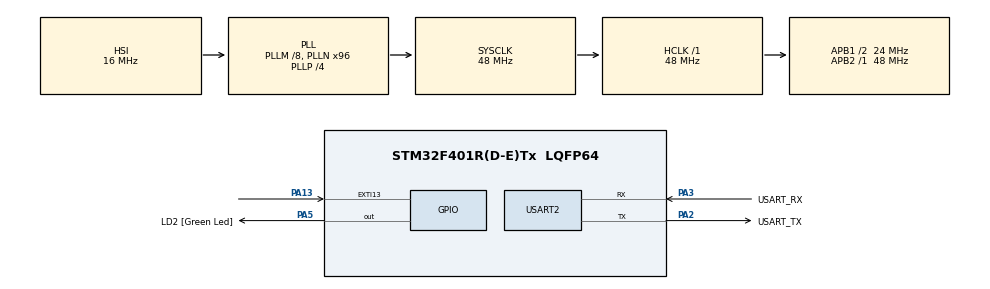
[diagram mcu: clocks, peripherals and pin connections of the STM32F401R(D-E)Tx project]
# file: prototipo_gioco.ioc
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Mcu.Family=STM32F4
Mcu.Name=STM32F401R(D-E)Tx
Mcu.Package=LQFP64
NVIC.EXTI15_10_IRQn=true\:0\:0\:false\:false\:true\:true\:true\:true
NVIC.PriorityGroup=NVIC_PRIORITYGROUP_4
NVIC.TIM2_IRQn=true\:0\:0\:false\:false\:true\:true\:true\:true
PA13.GPIO_ModeDefaultEXTI=GPIO_MODE_IT_FALLING
PA13.Signal=GPXTI13
PA14.GPIO_Label=TCK
PA14.Signal=SYS_JTCK-SWCLK
PA2.GPIO_Label=USART_TX
PA2.GPIO_Mode=GPIO_MODE_AF_PP
PA2.GPIO_PuPd=GPIO_NOPULL
PA2.GPIO_Speed=GPIO_SPEED_FREQ_LOW
PA2.Mode=Asynchronous
PA2.Signal=USART2_TX
PA3.GPIO_Label=USART_RX
PA3.GPIO_Mode=GPIO_MODE_AF_PP
PA3.GPIO_PuPd=GPIO_NOPULL
PA3.GPIO_Speed=GPIO_SPEED_FREQ_LOW
PA3.Mode=Asynchronous
PA3.Signal=USART2_RX
PA5.GPIO_Label=LD2 [Green Led]
PA5.GPIO_Mode=GPIO_MODE_OUTPUT_PP
PA5.GPIO_PuPd=GPIO_NOPULL
PA5.GPIO_Speed=GPIO_SPEED_FREQ_LOW
PA5.Signal=GPIO_Output
PB3.GPIO_Label=SWO
PB3.Signal=SYS_JTDO-SWO
PC14-OSC32_IN.Mode=LSE-External-Oscillator
PC14-OSC32_IN.Signal=RCC_OSC32_IN
PC15-OSC32_OUT.Mode=LSE-External-Oscillator
PC15-OSC32_OUT.Signal=RCC_OSC32_OUT
PH0\ -\ OSC_IN.Mode=HSE-External-Clock-Source
PH0\ -\ OSC_IN.Signal=RCC_OSC_IN
PH1\ -\ OSC_OUT.Mode=HSE-External-Clock-Source
PH1\ -\ OSC_OUT.Signal=RCC_OSC_OUT
ProjectManager.HeapSize=0x200
ProjectManager.StackSize=0x400
ProjectManager.TargetToolchain=STM32CubeIDE
RCC.48MHZClocksFreq_Value=27428571.42857143
RCC.AHBFreq_Value=48000000
RCC.APB1CLKDivider=RCC_HCLK_DIV2
RCC.APB1Freq_Value=24000000
RCC.APB1TimFreq_Value=48000000
RCC.APB2Freq_Value=48000000
RCC.APB2TimFreq_Value=48000000
RCC.CortexFreq_Value=48000000
RCC.HCLKFreq_Value=48000000
RCC.HSE_VALUE=8000000
RCC.HSI_VALUE=16000000
RCC.PLLM=8
RCC.PLLN=96
RCC.PLLP=RCC_PLLP_DIV4
RCC.PLLQ=7
RCC.SYSCLKFreq_VALUE=48000000
RCC.SYSCLKSource=RCC_SYSCLKSOURCE_PLLCLK
RCC.VCOOutputFreq_Value=192000000
TIM2.AutoReloadPreload=TIM_AUTORELOAD_PRELOAD_ENABLE
TIM2.Period=999
TIM2.Prescaler=47999
USART2.VirtualMode=VM_ASYNC
VP_TIM2_VS_ClockSourceINT.Mode=Internal
board=NUCLEO-F401RE

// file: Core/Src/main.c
/* USER CODE BEGIN Header */
/**
  ******************************************************************************
  * @file           : main.c
  * @brief          : Main program body
  ******************************************************************************
  */
/* USER CODE END Header */
#include "main.h"
#include "constants.h"
#include "game.h"
#include <stdio.h>   // Per printf
#include <stdlib.h>  // Per rand()

TIM_HandleTypeDef htim2;
UART_HandleTypeDef huart2;

/* USER CODE BEGIN PV */
volatile uint8_t buttonPressed = 0; // 0 se non premuto, 1 se premuto
volatile uint8_t start = 0;

int timer_value = 0; // valuta tempo di risposta

/* USER CODE END PV */

void SystemClock_Config(void);
static void MX_GPIO_Init(void);
static void MX_TIM2_Init(void);
static void MX_USART2_UART_Init(void);

/* USER CODE BEGIN PFP */
#ifdef __GNUC__
  #define PUTCHAR_PROTOTYPE int __io_putchar(int ch)
#else
  #define PUTCHAR_PROTOTYPE int fputc(int ch, FILE *f)
#endif

PUTCHAR_PROTOTYPE
{
  HAL_UART_Transmit(&huart2, (uint8_t *)&ch, 1, 0xFFFF);
  return ch;
}
/* USER CODE END PFP */

int main(void)
{
  /* Reset of all peripherals, Initializes the Flash interface and the Systick. */
  HAL_Init();

  /* Configure the system clock */
  SystemClock_Config();

  /* Initialize all configured peripherals */
  MX_GPIO_Init();
  MX_TIM2_Init();
  MX_USART2_UART_Init();

  /* USER CODE BEGIN 2 */
  // Leggiamo un valore a caso dalla memoria per inizializzare il random

  printf("\r\n=== RHYTHM GAME PROTOTYPE ===\r\n");
  //createDummySong();
  /* USER CODE END 2 */

  /* Infinite loop */
  /* USER CODE BEGIN WHILE */
  while (1)
  {
	  printf("press the button to start \n");
	  buttonPressed = 0; //to clear from older clicks
	  start = 1; // evaluate the button press

	  while (buttonPressed == 0){
		  //waiting for game to start
	  }
	  start = 0; //start phase finished
	  buttonPressed=0; //reset button to restart game
	  printf("\r\n game start! \r\n");
      printf("\r\nWAIT FOR THE LED TO TURN ON\r\n");

      // Aspetta un tempo casuale tra 2 e 5 secondi
      for(int i = 0; i < SONGLENGHT; i++){
      HAL_Delay(rand() % SECONDS + SECONDS_OFFSET);

      buttonPressed = 0;
      HAL_GPIO_WritePin(GPIOA, GPIO_PIN_5, GPIO_PIN_SET); // Accendi LD2
      printf("PRESS THE BUTTON!\r\n");

      // Azzera e fai partire il timer da 1 secondo
      __HAL_TIM_SET_COUNTER(&htim2, 0);
      HAL_TIM_Base_Start_IT(&htim2);

      // Aspetta che finisca il round (diamogli 2 secondi di pausa) prima di ripartire
      HAL_Delay(SPACE_BETWEEN_NOTES);

      // Assicuriamoci che il LED sia spento per il prossimo round
      HAL_GPIO_WritePin(GPIOA, GPIO_PIN_5, GPIO_PIN_RESET);
      }
	  finalScore(); //evaluates results
    printf("\r\n------GAME OVER, THANKS FOR PLAYING!------\r\n");
    /* USER CODE END WHILE */

  }
}

/* Callback del Pulsante (EXTI) */
/* USER CODE BEGIN 4 */
void HAL_GPIO_EXTI_Callback(uint16_t GPIO_Pin) {
    // PC13 è il Pin 13
    if (GPIO_Pin == GPIO_PIN_13 && buttonPressed == 0) {
        // Se il timer sta ancora girando (non ha fatto stop)
    	if (start == 1){
    		buttonPressed = 1;
    	}
    	else if (__HAL_TIM_GET_COUNTER(&htim2) > 0) {
            HAL_TIM_Base_Stop_IT(&htim2); // Ferma il timer! Hai vinto!
            timer_value = __HAL_TIM_GET_COUNTER(&htim2); //prendo valore timer
            buttonPressed = 1;
            HAL_GPIO_WritePin(GPIOA, GPIO_PIN_5, GPIO_PIN_RESET); // Spegni LED
            scoreEvaluate(timer_value);
        }
    }
}

/* Callback del Timer (Fine del tempo) */
void HAL_TIM_PeriodElapsedCallback(TIM_HandleTypeDef *htim) {
    if (htim->Instance == TIM2) {
        HAL_TIM_Base_Stop_IT(&htim2); // Ferma il timer per sicurezza

        if (buttonPressed == 0) { // Se non hai premuto in tempo
            HAL_GPIO_WritePin(GPIOA, GPIO_PIN_5, GPIO_PIN_RESET); // Spegni LED
            scoreEvaluate(MISSVALUE);
        }
    }
}
/* USER CODE END 4 */

void SystemClock_Config(void)
{
  RCC_OscInitTypeDef RCC_OscInitStruct = {0};
  RCC_ClkInitTypeDef RCC_ClkInitStruct = {0};

  __HAL_RCC_PWR_CLK_ENABLE();
  __HAL_PWR_VOLTAGESCALING_CONFIG(PWR_REGULATOR_VOLTAGE_SCALE2);

  RCC_OscInitStruct.OscillatorType = RCC_OSCILLATORTYPE_HSI;
  RCC_OscInitStruct.HSIState = RCC_HSI_ON;
  RCC_OscInitStruct.HSICalibrationValue = RCC_HSICALIBRATION_DEFAULT;
  RCC_OscInitStruct.PLL.PLLState = RCC_PLL_ON;
  RCC_OscInitStruct.PLL.PLLSource = RCC_PLLSOURCE_HSI;
  RCC_OscInitStruct.PLL.PLLM = 8;
  RCC_OscInitStruct.PLL.PLLN = 96;
  RCC_OscInitStruct.PLL.PLLP = RCC_PLLP_DIV4;
  RCC_OscInitStruct.PLL.PLLQ = 7;
  if (HAL_RCC_OscConfig(&RCC_OscInitStruct) != HAL_OK)
  {
    Error_Handler();
  }

  RCC_ClkInitStruct.ClockType = RCC_CLOCKTYPE_HCLK|RCC_CLOCKTYPE_SYSCLK
                              |RCC_CLOCKTYPE_PCLK1|RCC_CLOCKTYPE_PCLK2;
  RCC_ClkInitStruct.SYSCLKSource = RCC_SYSCLKSOURCE_PLLCLK;
  RCC_ClkInitStruct.AHBCLKDivider = RCC_SYSCLK_DIV1;
  RCC_ClkInitStruct.APB1CLKDivider = RCC_HCLK_DIV2;
  RCC_ClkInitStruct.APB2CLKDivider = RCC_HCLK_DIV1;

  if (HAL_RCC_ClockConfig(&RCC_ClkInitStruct, FLASH_LATENCY_1) != HAL_OK)
  {
    Error_Handler();
  }
}

static void MX_TIM2_Init(void)
{
  TIM_ClockConfigTypeDef sClockSourceConfig = {0};
  TIM_MasterConfigTypeDef sMasterConfig = {0};

  htim2.Instance = TIM2;
  htim2.Init.Prescaler = 47999;
  htim2.Init.CounterMode = TIM_COUNTERMODE_UP;
  htim2.Init.Period = 999;
  htim2.Init.ClockDivision = TIM_CLOCKDIVISION_DIV1;
  htim2.Init.AutoReloadPreload = TIM_AUTORELOAD_PRELOAD_ENABLE;
  if (HAL_TIM_Base_Init(&htim2) != HAL_OK)
  {
    Error_Handler();
  }
  sClockSourceConfig.ClockSource = TIM_CLOCKSOURCE_INTERNAL;
  if (HAL_TIM_ConfigClockSource(&htim2, &sClockSourceConfig) != HAL_OK)
  {
    Error_Handler();
  }
  sMasterConfig.MasterOutputTrigger = TIM_TRGO_RESET;
  sMasterConfig.MasterSlaveMode = TIM_MASTERSLAVEMODE_DISABLE;
  if (HAL_TIMEx_MasterConfigSynchronization(&htim2, &sMasterConfig) != HAL_OK)
  {
    Error_Handler();
  }
}

static void MX_USART2_UART_Init(void)
{
  huart2.Instance = USART2;
  huart2.Init.BaudRate = 115200;
  huart2.Init.WordLength = UART_WORDLENGTH_8B;
  huart2.Init.StopBits = UART_STOPBITS_1;
  huart2.Init.Parity = UART_PARITY_NONE;
  huart2.Init.Mode = UART_MODE_TX_RX;
  huart2.Init.HwFlowCtl = UART_HWCONTROL_NONE;
  huart2.Init.OverSampling = UART_OVERSAMPLING_16;
  if (HAL_UART_Init(&huart2) != HAL_OK)
  {
    Error_Handler();
  }
}

static void MX_GPIO_Init(void)
{
  GPIO_InitTypeDef GPIO_InitStruct = {0};

  /* GPIO Ports Clock Enable */
  __HAL_RCC_GPIOC_CLK_ENABLE(); // ABILITATO PORT C PER IL PULSANTE
  __HAL_RCC_GPIOH_CLK_ENABLE();
  __HAL_RCC_GPIOA_CLK_ENABLE();
  __HAL_RCC_GPIOB_CLK_ENABLE();

  /*Configure GPIO pin Output Level */
  HAL_GPIO_WritePin(GPIOA, GPIO_PIN_5, GPIO_PIN_RESET);

  /*Configure GPIO pin : PA5 (LED) */
  GPIO_InitStruct.Pin = GPIO_PIN_5;
  GPIO_InitStruct.Mode = GPIO_MODE_OUTPUT_PP;
  GPIO_InitStruct.Pull = GPIO_NOPULL;
  GPIO_InitStruct.Speed = GPIO_SPEED_FREQ_LOW;
  HAL_GPIO_Init(GPIOA, &GPIO_InitStruct);

  /*Configure GPIO pin : PC13 (PULSANTE BLU) */
  GPIO_InitStruct.Pin = GPIO_PIN_13;
  GPIO_InitStruct.Mode = GPIO_MODE_IT_FALLING; // Attivazione sul rilascio/pressione
  GPIO_InitStruct.Pull = GPIO_NOPULL;
  HAL_GPIO_Init(GPIOC, &GPIO_InitStruct); // ATTENZIONE: ORA E' GPIOC!

  /* EXTI interrupt init*/
  HAL_NVIC_SetPriority(EXTI15_10_IRQn, 0, 0);
  HAL_NVIC_EnableIRQ(EXTI15_10_IRQn);
}

void Error_Handler(void)
{
  __disable_irq();
  while (1)
  {
  }
}
